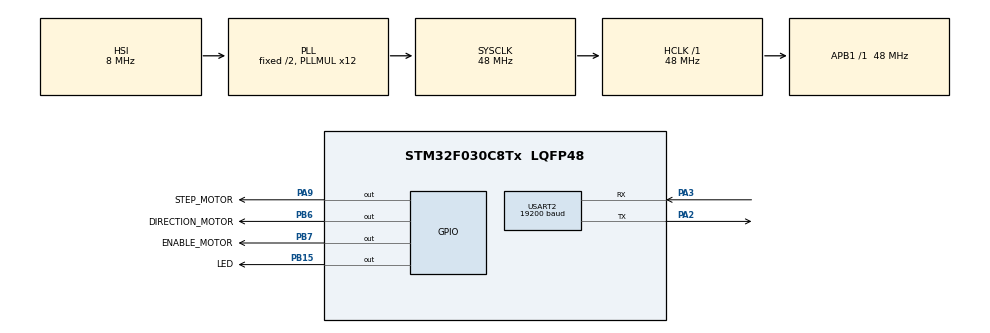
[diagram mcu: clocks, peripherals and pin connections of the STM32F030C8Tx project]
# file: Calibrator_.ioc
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Mcu.Family=STM32F0
Mcu.Name=STM32F030C8Tx
Mcu.Package=LQFP48
NVIC.TIM1_BRK_UP_TRG_COM_IRQn=true\:0\:0\:false\:false\:true\:true\:true
NVIC.TIM1_CC_IRQn=true\:0\:0\:false\:false\:true\:true\:true
NVIC.USART2_IRQn=true\:0\:0\:false\:false\:true\:true\:true
PA2.Mode=Asynchronous
PA2.Signal=USART2_TX
PA3.Mode=Asynchronous
PA3.Signal=USART2_RX
PA9.GPIO_Label=STEP_MOTOR
PA9.Signal=GPIO_Output
PB15.GPIO_Label=LED
PB15.Signal=GPIO_Output
PB6.GPIO_Label=DIRECTION_MOTOR
PB6.Signal=GPIO_Output
PB7.GPIO_Label=ENABLE_MOTOR
PB7.Signal=GPIO_Output
PF0-OSC_IN.Mode=HSE-External-Oscillator
PF0-OSC_IN.Signal=RCC_OSC_IN
PF1-OSC_OUT.Mode=HSE-External-Oscillator
PF1-OSC_OUT.Signal=RCC_OSC_OUT
ProjectManager.HeapSize=0x200
ProjectManager.StackSize=0x400
ProjectManager.TargetToolchain=STM32CubeIDE
RCC.AHBFreq_Value=48000000
RCC.APB1Freq_Value=48000000
RCC.APB1TimFreq_Value=48000000
RCC.HCLKFreq_Value=48000000
RCC.HSE_VALUE=16000000
RCC.PLLMUL=RCC_PLL_MUL12
RCC.SYSCLKFreq_VALUE=48000000
RCC.SYSCLKSource=RCC_SYSCLKSOURCE_PLLCLK
TIM1.AutoReloadPreload=TIM_AUTORELOAD_PRELOAD_ENABLE
TIM1.Channel-Output\ Compare1\ No\ Output=TIM_CHANNEL_1
TIM1.ClockDivision=TIM_CLOCKDIVISION_DIV1
TIM1.Period=1000
TIM1.Prescaler=47
TIM1.Pulse-Output\ Compare1\ No\ Output=500
USART2.BaudRate=19200
USART2.VirtualMode-Asynchronous=VM_ASYNC
VP_TIM1_VS_ClockSourceINT.Mode=Internal
VP_TIM1_VS_no_output1.Mode=Output Compare1 No Output
board=custom

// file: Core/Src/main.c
/* USER CODE BEGIN Header */
/**
  ******************************************************************************
  * @file           : main.c
  * @brief          : Main program body
  ******************************************************************************
  * @attention
  *
  * <h2><center>&copy; Copyright (c) 2022 STMicroelectronics.
  * All rights reserved.</center></h2>
  *
  * This software component is licensed by ST under BSD 3-Clause license,
  * the "License"; You may not use this file except in compliance with the
  * License. You may obtain a copy of the License at:
  *                        opensource.org/licenses/BSD-3-Clause
  *
  ******************************************************************************
  */
/* USER CODE END Header */
#include "main.h"

/* USER CODE BEGIN Includes */
#include "application.h"
/* USER CODE END Includes */

/* USER CODE BEGIN PTD */
#define    DWT_CYCCNT    *(volatile uint32_t *)0xE0001004
#define    DWT_CONTROL   *(volatile uint32_t *)0xE0001000
#define    SCB_DEMCR     *(volatile uint32_t *)0xE000EDFC
/* USER CODE END PTD */

TIM_HandleTypeDef htim1;

UART_HandleTypeDef huart2;

void SystemClock_Config(void);
static void MX_GPIO_Init(void);
static void MX_USART2_UART_Init(void);
static void MX_TIM1_Init(void);
/* USER CODE BEGIN PFP */
void app_main();
/* USER CODE END PFP */

int main(void)
{

  /* MCU Configuration--------------------------------------------------------*/

  /* Reset of all peripherals, Initializes the Flash interface and the Systick. */
  HAL_Init();

  /* Configure the system clock */
  SystemClock_Config();

  /* Initialize all configured peripherals */
  MX_GPIO_Init();
  MX_USART2_UART_Init();
  MX_TIM1_Init();

  /* Infinite loop */
  /* USER CODE BEGIN WHILE */
  while (1)
  {
	app_main();
    /* USER CODE END WHILE */

  }
}

void SystemClock_Config(void)
{
  RCC_OscInitTypeDef RCC_OscInitStruct = {0};
  RCC_ClkInitTypeDef RCC_ClkInitStruct = {0};

  /** Initializes the RCC Oscillators according to the specified parameters
  * in the RCC_OscInitTypeDef structure.
  */
  RCC_OscInitStruct.OscillatorType = RCC_OSCILLATORTYPE_HSI;
  RCC_OscInitStruct.HSIState = RCC_HSI_ON;
  RCC_OscInitStruct.HSICalibrationValue = RCC_HSICALIBRATION_DEFAULT;
  RCC_OscInitStruct.PLL.PLLState = RCC_PLL_ON;
  RCC_OscInitStruct.PLL.PLLSource = RCC_PLLSOURCE_HSI;
  RCC_OscInitStruct.PLL.PLLMUL = RCC_PLL_MUL12;
  RCC_OscInitStruct.PLL.PREDIV = RCC_PREDIV_DIV1;
  if (HAL_RCC_OscConfig(&RCC_OscInitStruct) != HAL_OK)
  {
    Error_Handler();
  }
  /** Initializes the CPU, AHB and APB buses clocks
  */
  RCC_ClkInitStruct.ClockType = RCC_CLOCKTYPE_HCLK|RCC_CLOCKTYPE_SYSCLK
                              |RCC_CLOCKTYPE_PCLK1;
  RCC_ClkInitStruct.SYSCLKSource = RCC_SYSCLKSOURCE_PLLCLK;
  RCC_ClkInitStruct.AHBCLKDivider = RCC_SYSCLK_DIV1;
  RCC_ClkInitStruct.APB1CLKDivider = RCC_HCLK_DIV1;

  if (HAL_RCC_ClockConfig(&RCC_ClkInitStruct, FLASH_LATENCY_1) != HAL_OK)
  {
    Error_Handler();
  }
}

static void MX_TIM1_Init(void)
{

  TIM_ClockConfigTypeDef sClockSourceConfig = {0};
  TIM_MasterConfigTypeDef sMasterConfig = {0};
  TIM_OC_InitTypeDef sConfigOC = {0};
  TIM_BreakDeadTimeConfigTypeDef sBreakDeadTimeConfig = {0};

  htim1.Instance = TIM1;
  htim1.Init.Prescaler = 47;
  htim1.Init.CounterMode = TIM_COUNTERMODE_UP;
  htim1.Init.Period = 1000;
  htim1.Init.ClockDivision = TIM_CLOCKDIVISION_DIV1;
  htim1.Init.RepetitionCounter = 0;
  htim1.Init.AutoReloadPreload = TIM_AUTORELOAD_PRELOAD_ENABLE;
  if (HAL_TIM_Base_Init(&htim1) != HAL_OK)
  {
    Error_Handler();
  }
  sClockSourceConfig.ClockSource = TIM_CLOCKSOURCE_INTERNAL;
  if (HAL_TIM_ConfigClockSource(&htim1, &sClockSourceConfig) != HAL_OK)
  {
    Error_Handler();
  }
  if (HAL_TIM_OC_Init(&htim1) != HAL_OK)
  {
    Error_Handler();
  }
  sMasterConfig.MasterOutputTrigger = TIM_TRGO_RESET;
  sMasterConfig.MasterSlaveMode = TIM_MASTERSLAVEMODE_DISABLE;
  if (HAL_TIMEx_MasterConfigSynchronization(&htim1, &sMasterConfig) != HAL_OK)
  {
    Error_Handler();
  }
  sConfigOC.OCMode = TIM_OCMODE_TIMING;
  sConfigOC.Pulse = 500;
  sConfigOC.OCPolarity = TIM_OCPOLARITY_HIGH;
  sConfigOC.OCNPolarity = TIM_OCNPOLARITY_HIGH;
  sConfigOC.OCFastMode = TIM_OCFAST_DISABLE;
  sConfigOC.OCIdleState = TIM_OCIDLESTATE_RESET;
  sConfigOC.OCNIdleState = TIM_OCNIDLESTATE_RESET;
  if (HAL_TIM_OC_ConfigChannel(&htim1, &sConfigOC, TIM_CHANNEL_1) != HAL_OK)
  {
    Error_Handler();
  }
  sBreakDeadTimeConfig.OffStateRunMode = TIM_OSSR_DISABLE;
  sBreakDeadTimeConfig.OffStateIDLEMode = TIM_OSSI_DISABLE;
  sBreakDeadTimeConfig.LockLevel = TIM_LOCKLEVEL_OFF;
  sBreakDeadTimeConfig.DeadTime = 0;
  sBreakDeadTimeConfig.BreakState = TIM_BREAK_DISABLE;
  sBreakDeadTimeConfig.BreakPolarity = TIM_BREAKPOLARITY_HIGH;
  sBreakDeadTimeConfig.AutomaticOutput = TIM_AUTOMATICOUTPUT_DISABLE;
  if (HAL_TIMEx_ConfigBreakDeadTime(&htim1, &sBreakDeadTimeConfig) != HAL_OK)
  {
    Error_Handler();
  }

}

static void MX_USART2_UART_Init(void)
{

  huart2.Instance = USART2;
  huart2.Init.BaudRate = 19200;
  huart2.Init.WordLength = UART_WORDLENGTH_8B;
  huart2.Init.StopBits = UART_STOPBITS_1;
  huart2.Init.Parity = UART_PARITY_NONE;
  huart2.Init.Mode = UART_MODE_TX_RX;
  huart2.Init.HwFlowCtl = UART_HWCONTROL_NONE;
  huart2.Init.OverSampling = UART_OVERSAMPLING_16;
  huart2.Init.OneBitSampling = UART_ONE_BIT_SAMPLE_DISABLE;
  huart2.AdvancedInit.AdvFeatureInit = UART_ADVFEATURE_NO_INIT;
  if (HAL_UART_Init(&huart2) != HAL_OK)
  {
    Error_Handler();
  }

}

static void MX_GPIO_Init(void)
{
  GPIO_InitTypeDef GPIO_InitStruct = {0};

  /* GPIO Ports Clock Enable */
  __HAL_RCC_GPIOF_CLK_ENABLE();
  __HAL_RCC_GPIOA_CLK_ENABLE();
  __HAL_RCC_GPIOB_CLK_ENABLE();

  /*Configure GPIO pin Output Level */
  HAL_GPIO_WritePin(GPIOB, LED_Pin|DIRECTION_MOTOR_Pin|ENABLE_MOTOR_Pin, GPIO_PIN_RESET);

  /*Configure GPIO pin Output Level */
  HAL_GPIO_WritePin(STEP_MOTOR_GPIO_Port, STEP_MOTOR_Pin, GPIO_PIN_RESET);

  /*Configure GPIO pins : LED_Pin DIRECTION_MOTOR_Pin ENABLE_MOTOR_Pin */
  GPIO_InitStruct.Pin = LED_Pin|DIRECTION_MOTOR_Pin|ENABLE_MOTOR_Pin;
  GPIO_InitStruct.Mode = GPIO_MODE_OUTPUT_PP;
  GPIO_InitStruct.Pull = GPIO_NOPULL;
  GPIO_InitStruct.Speed = GPIO_SPEED_FREQ_LOW;
  HAL_GPIO_Init(GPIOB, &GPIO_InitStruct);

  /*Configure GPIO pin : STEP_MOTOR_Pin */
  GPIO_InitStruct.Pin = STEP_MOTOR_Pin;
  GPIO_InitStruct.Mode = GPIO_MODE_OUTPUT_PP;
  GPIO_InitStruct.Pull = GPIO_NOPULL;
  GPIO_InitStruct.Speed = GPIO_SPEED_FREQ_LOW;
  HAL_GPIO_Init(STEP_MOTOR_GPIO_Port, &GPIO_InitStruct);

}

/* USER CODE BEGIN 4 */
//void Stepper_motor(int8_t Direction,uint32_t Steps)
//{
//	HAL_GPIO_WritePin(EN_GPIO_Port, EN_Pin, RESET);
//	switch (Direction) {
//		case 1:
//			HAL_GPIO_WritePin(CW_GPIO_Port, CW_Pin, SET);
//			break;
//		default:
//			HAL_GPIO_WritePin(CW_GPIO_Port, CW_Pin, RESET);
//			break;
//	}
//	for(uint32_t i=0;i<=2*Steps-1;i++){
//		HAL_GPIO_TogglePin(CLK_GPIO_Port, CLK_Pin);
//		Delay_ms(tmp_2);
//	}
//	HAL_GPIO_WritePin(CLK_GPIO_Port, CLK_Pin, RESET);
//	HAL_GPIO_WritePin(EN_GPIO_Port, EN_Pin, SET);
//}

void Delay_ms(uint32_t ms)
{
//	DWT->CYCCNT = 0; // сброс счётчика
//	while(DWT->CYCCNT < ms*168) {} // задержка 5 мкс (5 * 72 )
}
/* USER CODE END 4 */

void Error_Handler(void)
{
  __disable_irq();
  while (1)
  {
  }
}

/************************ (C) COPYRIGHT STMicroelectronics *****END OF FILE****/
